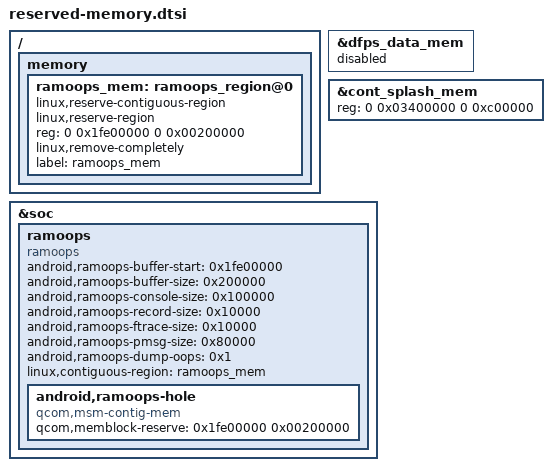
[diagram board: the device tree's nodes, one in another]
&dfps_data_mem {
	status = "disabled";
};

&cont_splash_mem {
	reg = <0 0x03400000 0 0xc00000>;
};

/* ref: msm8937.dtsi */

/ {
    memory {
	#address-cells = <2>;
	#size-cells = <2>;

        ramoops_mem: ramoops_region@0 {
	  linux,reserve-contiguous-region;
	  linux,reserve-region;
	  reg = <0 0x1fe00000 0 0x00200000>;
	  linux,remove-completely;
	  label = "ramoops_mem";
	};
    };
};

   &soc {
	ramoops {
		compatible = "ramoops";
		status = "ok";

		android,ramoops-buffer-start = <0x1fe00000>;
		android,ramoops-buffer-size = <0x200000>;
		android,ramoops-console-size = <0x100000>;
		android,ramoops-record-size = <0x10000>;
		android,ramoops-ftrace-size = <0x10000>;
		android,ramoops-pmsg-size = <0x80000>;
		android,ramoops-dump-oops = <0x1>;
		linux,contiguous-region = <&ramoops_mem>;
		android,ramoops-hole {
			compatible = "qcom,msm-contig-mem";
			qcom,memblock-reserve = <0x1fe00000 0x00200000>;
		};
	};
   };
